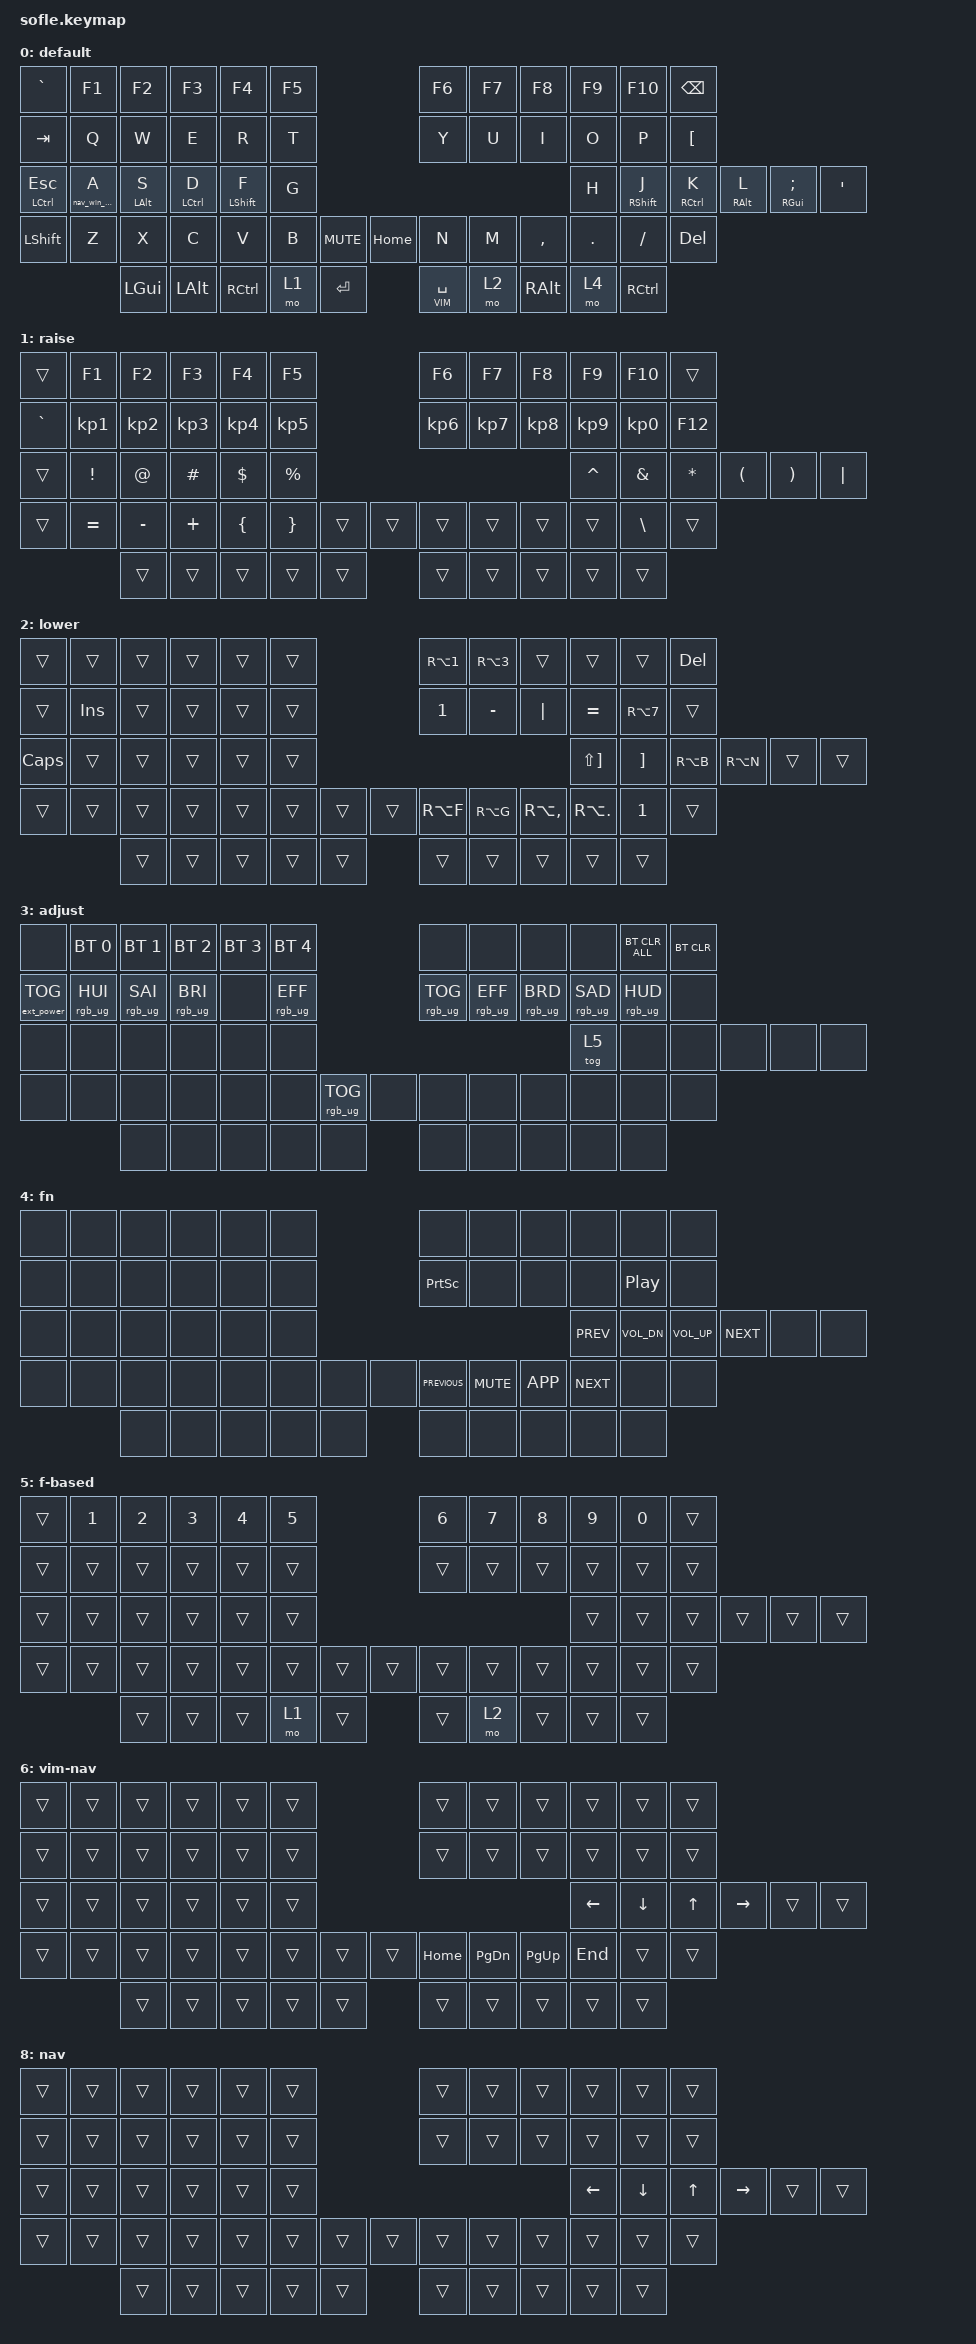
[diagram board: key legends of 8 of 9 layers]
/*
 * Copyright (c) 2020 The ZMK Contributors
 *
 * SPDX-License-Identifier: MIT
 */

#include <behaviors.dtsi>
#include <dt-bindings/zmk/bt.h>
#include <dt-bindings/zmk/ext_power.h>
#include <dt-bindings/zmk/keys.h>
#include <dt-bindings/zmk/rgb.h>

#if IS_ENABLED(CONFIG_SHIELD_NICE_VIEW_ADAPTER)
#include "hardware.dtsi"
#endif

#define BASE 0
#define LOWER 1
#define RAISE 2
#define ADJUST 3
#define FN 4
#define VIM 6
#define NUM 7
#define NAV 8



/ {
    behaviors {
        hm: homerow_mods {
            compatible = "zmk,behavior-hold-tap";
            #binding-cells = <2>;
            tapping-term-ms = <200>;
            quick-tap-ms = <125>;
            require-prior-idle-ms = <50>;
            flavor = "balanced";
            bindings = <&kp>, <&kp>;
        };

        hm_r: homerow_mods_right {
            compatible = "zmk,behavior-hold-tap";
            #binding-cells = <2>;
            tapping-term-ms = <200>;
            quick-tap-ms = <125>;
            require-prior-idle-ms = <50>;
            flavor = "balanced";
            bindings = <&kp>, <&kp>;
            hold-trigger-key-positions = <0 1 2 3 4 5 12 13 14 15 16 17 24 25 26 27 28 29 36 37 38 39 40 41 50 51 52 53 54>;
            hold-trigger-on-release;
        };

        lt_spc: layer_tap_space {
            compatible = "zmk,behavior-hold-tap";
            #binding-cells = <2>;
            tapping-term-ms = <200>;
            quick-tap-ms = <125>;
            flavor = "balanced";
            bindings = <&mo>, <&kp>;
        };

        ctrl_esc: ctrl_escape {
            compatible = "zmk,behavior-hold-tap";
            #binding-cells = <2>;
            tapping-term-ms = <200>;
            quick-tap-ms = <125>;
            flavor = "tap-preferred";
            bindings = <&kp>, <&kp>;
        };

        lt_nav: lt_nav_win {
            compatible = "zmk,behavior-hold-tap";
            #binding-cells = <2>;
            tapping-term-ms = <200>;
            quick-tap-ms = <125>;
            flavor = "tap-preferred";
            bindings = <&nav_win_hold>, <&kp>;
        };
    };

    macros {
        nav_win_hold: nav_win_hold {
            compatible = "zmk,behavior-macro-one-param";
            #binding-cells = <1>;
            wait-ms = <0>;
            tap-ms = <0>;
            bindings = <&macro_press &mo NAV &kp LGUI>,
                       <&macro_pause_for_release>,
                       <&macro_release &kp LGUI &mo NAV>;
        };
    };

    combos {
        compatible = "zmk,combos";

        combo_num_layer {
            timeout-ms = <50>;
            key-positions = <27 28>;
            bindings = <&mo NUM>;
        };
    };

    // Activate ADJUST layer by pressing raise and lower

    conditional_layers {
        compatible = "zmk,conditional-layers";

        adjust_layer {
            if-layers = <1 2>;
            then-layer = <3>;
        };
    };

    keymap {
        compatible = "zmk,keymap";

        default_layer {
            display-name = "default";
            bindings = <
&kp GRAVE  &kp F1  &kp F2    &kp F3    &kp F4     &kp F5                           &kp F6  &kp F7         &kp F8     &kp F9             &kp F10   &kp BSPC
&kp TAB    &kp Q   &kp W     &kp E     &kp R      &kp T                            &kp Y   &kp U          &kp I      &kp O              &kp P     &kp LBKT
&ctrl_esc LCTRL ESC   &lt_nav 0 A   &hm LALT S   &hm LCTRL D   &hm LSHFT F   &kp G                            &kp H   &hm_r RSHFT J   &hm_r RCTRL K   &hm_r RALT L   &hm_r RGUI SEMI  &kp SINGLE_QUOTE
&kp LSHFT  &kp Z   &kp X     &kp C     &kp V      &kp B   &kp C_MUTE    &kp HOME   &kp N   &kp M          &kp COMMA  &kp DOT            &kp FSLH  &kp DEL
                   &kp LGUI  &kp LALT  &kp RCTRL  &mo 1   &kp ENTER     &lt_spc VIM SPACE  &mo 2   &kp RIGHT_ALT  &mo 4      &kp RIGHT_CONTROL
            >;

            // sensor-bindings = <&inc_dec_kp C_VOL_UP C_VOL_DN &inc_dec_kp PG_UP PG_DN>;
        };

        raise_layer {
            display-name = "raise";
            bindings = <
&trans     &kp F1     &kp F2     &kp F3     &kp F4     &kp F5                       &kp F6     &kp F7     &kp F8     &kp F9     &kp F10    &trans
&kp GRAVE  &kp KP_N1  &kp KP_N2  &kp KP_N3  &kp KP_N4  &kp KP_N5                    &kp KP_N6  &kp KP_N7  &kp KP_N8  &kp KP_N9  &kp KP_N0  &kp F12
&trans     &kp EXCL   &kp AT     &kp HASH   &kp DLLR   &kp PRCNT                    &kp CARET  &kp AMPS   &kp ASTRK  &kp LPAR   &kp RPAR   &kp PIPE
&trans     &kp EQUAL  &kp MINUS  &kp PLUS   &kp LBRC   &kp RBRC   &trans    &trans  &trans     &trans     &trans     &trans     &kp BSLH   &trans
                      &trans     &trans     &trans     &trans     &trans    &trans  &trans     &trans     &trans     &trans
            >;

            // sensor-bindings = <&inc_dec_kp C_VOL_UP C_VOL_DN &inc_dec_kp PG_UP PG_DN>;
        };

        lower_layer {
            display-name = "lower";
            bindings = <
&trans    &trans   &trans  &trans  &trans  &trans                    &kp RA(N1)    &kp RA(NUMBER_3)  &trans         &trans       &trans            &kp DEL
&trans    &kp INS  &trans  &trans  &trans  &trans                    &kp NUMBER_1  &kp MINUS         &kp PIPE       &kp EQUAL    &kp RA(NUMBER_7)  &trans
&kp CLCK  &trans   &trans  &trans  &trans  &trans                    &kp LS(RBKT)  &kp RBKT          &kp RA(B)      &kp RA(N)    &trans            &trans
&trans    &trans   &trans  &trans  &trans  &trans  &trans    &trans  &kp RA(F)     &kp RA(G)         &kp RA(COMMA)  &kp RA(DOT)  &kp NUMBER_1      &trans
                   &trans  &trans  &trans  &trans  &trans    &trans  &trans        &trans            &trans         &trans
            >;

            // sensor-bindings = <&inc_dec_kp C_VOL_UP C_VOL_DN &inc_dec_kp PG_UP PG_DN>;
        };

        adjust_layer {
            display-name = "adjust";
            bindings = <
&none              &bt BT_SEL 0     &bt BT_SEL 1     &bt BT_SEL 2     &bt BT_SEL 3  &bt BT_SEL 4                               &none            &none            &none            &none            &bt BT_CLR_ALL   &bt BT_CLR
&ext_power EP_TOG  &rgb_ug RGB_HUI  &rgb_ug RGB_SAI  &rgb_ug RGB_BRI  &none         &rgb_ug RGB_EFF                            &rgb_ug RGB_TOG  &rgb_ug RGB_EFF  &rgb_ug RGB_BRD  &rgb_ug RGB_SAD  &rgb_ug RGB_HUD  &none
&none              &none            &none            &none            &none         &none                                      &tog 5           &none            &none            &none            &none            &none
&none              &none            &none            &none            &none         &none            &rgb_ug RGB_TOG    &none  &none            &none            &none            &none            &none            &none
                                    &none            &none            &none         &none            &none              &none  &none            &none            &none            &none
            >;
        };

        fn {
            bindings = <
&none  &none  &none  &none  &none  &none                  &none            &none         &none         &none       &none             &none
&none  &none  &none  &none  &none  &none                  &kp PRINTSCREEN  &none         &none         &none       &kp C_PLAY_PAUSE  &none
&none  &none  &none  &none  &none  &none                  &kp C_PREV       &kp C_VOL_DN  &kp C_VOL_UP  &kp C_NEXT  &none             &none
&none  &none  &none  &none  &none  &none  &none    &none  &kp K_PREVIOUS   &kp C_MUTE    &kp K_APP     &kp K_NEXT  &none             &none
              &none  &none  &none  &none  &none    &none  &none            &none         &none         &none
            >;

            // sensor-bindings = <&inc_dec_kp 0 0>, <&inc_dec_kp 0 0>;
        };

        f-based {
            display-name = "f-based";
            bindings = <
&trans  &kp N1  &kp N2  &kp N3  &kp N4  &kp N5                    &kp N6  &kp N7  &kp N8  &kp N9  &kp N0  &trans
&trans  &trans  &trans  &trans  &trans  &trans                    &trans  &trans  &trans  &trans  &trans  &trans
&trans  &trans  &trans  &trans  &trans  &trans                    &trans  &trans  &trans  &trans  &trans  &trans
&trans  &trans  &trans  &trans  &trans  &trans  &trans    &trans  &trans  &trans  &trans  &trans  &trans  &trans
                &trans  &trans  &trans  &mo 1   &trans    &trans  &mo 2   &trans  &trans  &trans
            >;
        };

        vim_nav {
            display-name = "vim-nav";
            bindings = <
&trans  &trans  &trans  &trans  &trans  &trans                    &trans    &trans    &trans    &trans   &trans   &trans
&trans  &trans  &trans  &trans  &trans  &trans                    &trans    &trans    &trans    &trans   &trans   &trans
&trans  &trans  &trans  &trans  &trans  &trans                    &kp LEFT  &kp DOWN  &kp UP    &kp RIGHT  &trans  &trans
&trans  &trans  &trans  &trans  &trans  &trans  &trans    &trans  &kp HOME  &kp PG_DN &kp PG_UP &kp END  &trans   &trans
                &trans  &trans  &trans  &trans  &trans    &trans  &trans    &trans    &trans    &trans
            >;
        };

        num_layer {
            display-name = "numbers";
            bindings = <
&trans  &trans  &trans  &trans  &trans  &trans                    &trans       &trans         &kp KP_SLASH   &kp KP_ASTERISK  &kp KP_MINUS   &trans
&trans  &trans  &trans  &trans  &trans  &trans                    &trans       &kp KP_N7      &kp KP_N8        &kp KP_N9      &kp KP_PLUS   &trans
&trans  &trans  &trans  &trans  &trans  &trans                    &trans       &kp KP_N4      &kp KP_N5        &kp KP_N6      &kp KP_PLUS   &trans
&trans  &trans  &trans  &trans  &trans  &trans  &trans    &trans  &trans       &kp KP_N1      &kp KP_N2        &kp KP_N3      &kp KP_ENTER  &trans
                &trans  &trans  &trans  &trans  &trans    &trans  &kp KP_N0    &kp KP_N0      &kp KP_DOT       &kp KP_ENTER   &trans
            >;
        };

        nav_layer {
            display-name = "nav";
            bindings = <
&trans  &trans  &trans  &trans  &trans  &trans                    &trans    &trans    &trans    &trans     &trans  &trans
&trans  &trans  &trans  &trans  &trans  &trans                    &trans    &trans    &trans    &trans     &trans  &trans
&trans  &trans  &trans  &trans  &trans  &trans                    &kp LEFT  &kp DOWN  &kp UP    &kp RIGHT  &trans  &trans
&trans  &trans  &trans  &trans  &trans  &trans  &trans    &trans  &trans    &trans    &trans    &trans     &trans  &trans
                &trans  &trans  &trans  &trans  &trans    &trans  &trans    &trans    &trans    &trans
            >;
        };
    };
};
